# LPC55S6x register map
Vendor: nxp.com; File version: 1.0
CPU: CM33 r2p0, little endian, MPU, FPU, VTOR, 3 interrupt priority bits
Registers are 32-bit, read-write, reset 0x0 unless marked. A register's access mark holds for its fields unless they carry their own. Offsets are from the block's base; [hi:lo] are bit positions; {n}, {i} and the like mark numbered series.

## WWDT — Windowed Watchdog Timer (WWDT)
Base 0x4000C000
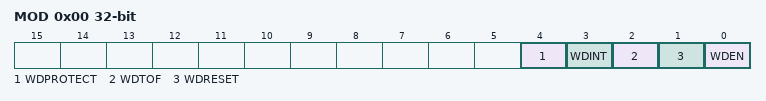
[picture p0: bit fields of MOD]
0x00 MOD — Watchdog mode register. This register contains the basic mode and status of the Watchdog Timer.
  [4] WDPROTECT — Watchdog update mode. This bit can be set once by software and is only cleared by a reset.
    0=FLEXIBLE (Flexible. The watchdog time-out value (TC) can be changed at any time.); 1=THRESHOLD (Threshold. The watchdog time-out value (TC) can be changed only after the counter is below the value of WDWARNINT and WDWINDOW.)
  [3] WDINT — Warning interrupt flag. Set when the timer is at or below the value in WDWARNINT. Cleared by software writing a 1 to this bit position. Note that this bit cannot be cleared while the WARNINT value is equal to the value of the TV register. This can occur if the value of WARNINT is 0 and the WDRESET bit is 0 when TV decrements to 0.
  [2] WDTOF — Watchdog time-out flag. Set when the watchdog timer times out, by a feed error, or by events associated with WDPROTECT. Cleared by software writing a 0 to this bit position. Causes a chip reset if WDRESET = 1.
  [1] WDRESET — Watchdog reset enable bit. Once this bit has been written with a 1 it cannot be re-written with a 0.
    0=INTERRUPT (Interrupt. A watchdog time-out will not cause a chip reset.); 1=RESET (Reset. A watchdog time-out will cause a chip reset.)
  [0] WDEN — Watchdog enable bit. Once this bit is set to one and a watchdog feed is performed, the watchdog timer will run permanently.
    0=STOP (Stop. The watchdog timer is stopped.); 1=RUN (Run. The watchdog timer is running.)
0x04 TC reset 0xFF — Watchdog timer constant register. This 24-bit register determines the time-out value.
  [23:0] COUNT — Watchdog time-out value.
0x08 FEED wo reset not defined — Watchdog feed sequence register. Writing 0xAA followed by 0x55 to this register reloads the Watchdog timer with the value contained in TC.
  [7:0] FEED — Feed value should be 0xAA followed by 0x55.
0x0C TV ro reset 0xFF — Watchdog timer value register. This 24-bit register reads out the current value of the Watchdog timer.
  [23:0] COUNT — Counter timer value.
0x14 WARNINT — Watchdog Warning Interrupt compare value.
  [9:0] WARNINT — Watchdog warning interrupt compare value.
0x18 WINDOW reset 0xFFFFFF — Watchdog Window compare value.
  [23:0] WINDOW — Watchdog window value.

## UTICK0 — Micro-tick Timer (UTICK)
Base 0x4000E000
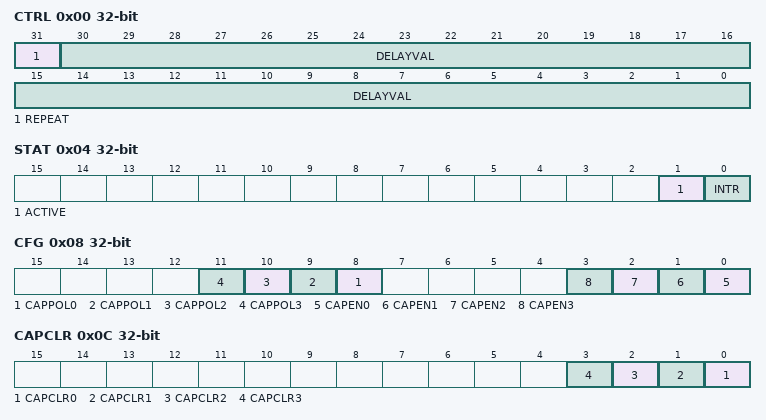
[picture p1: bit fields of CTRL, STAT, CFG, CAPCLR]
0x00 CTRL — Control register.
  [31] REPEAT — Repeat delay. 0 = One-time delay. 1 = Delay repeats continuously.
  [30:0] DELAYVAL — Tick interval value. The delay will be equal to DELAYVAL + 1 periods of the timer clock. The minimum usable value is 1, for a delay of 2 timer clocks. A value of 0 stops the timer.
0x04 STAT — Status register.
  [1] ACTIVE — Active flag. 0 = The Micro-Tick Timer is stopped. 1 = The Micro-Tick Timer is currently active.
  [0] INTR — Interrupt flag. 0 = No interrupt is pending. 1 = An interrupt is pending. A write of any value to this register clears this flag.
0x08 CFG — Capture configuration register.
  [n+8] CAPPOL{n} (n=0..3) — Capture Polarity {n}. 0 = Positive edge capture, 1 = Negative edge capture.
  [n] CAPEN{n} (n=0..3) — Enable Capture {n}. 1 = Enabled, 0 = Disabled.
0x0C CAPCLR wo reset not defined — Capture clear register.
  [n] CAPCLR{n} (n=0..3) — Clear capture {n}. Writing 1 to this bit clears the CAP{n} register value.
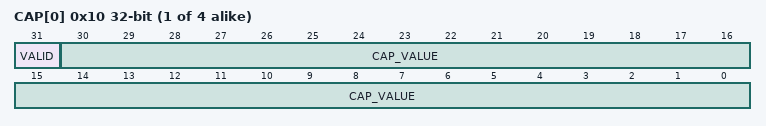
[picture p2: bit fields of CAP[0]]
{0x10+4i} CAP[{i}] (i=0..3) ro — Capture register .
  [31] VALID — Capture Valid. When 1, a value has been captured based on a transition of the related UTICK_CAPn pin. Cleared by writing to the related bit in the CAPCLR register.
  [30:0] CAP_VALUE — Capture value for the related capture event (UTICK_CAPn. Note: the value is 1 lower than the actual value of the Micro-tick Timer at the moment of the capture event.

## Notices in the file
Copyright 2016-2019 NXP
All rights reserved.
SPDX-License-Identifier: BSD-3-Clause
